# CORTEXA9_WUGEN register map
Vendor: Texas Instruments
Peripheral module from a debugger description file (folder omap4460).
Registers are 32-bit, access per field, reset 0xFFFFFFFF unless marked. A register's access mark holds for its fields unless they carry their own. Offsets are as the file gives them; lines under a group give offsets from that group; [hi:lo] are bit positions; {n}, {i} and the like mark numbered series; 'fields as' and 'values as' point back to an identical list; <NAME> marks a mode.

## CORTEXA9_WUGEN
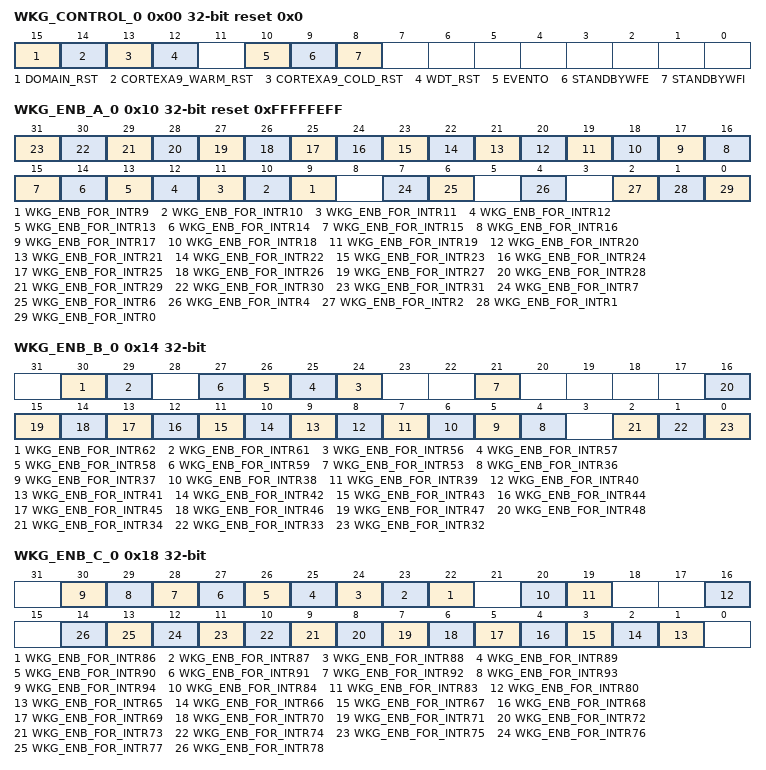
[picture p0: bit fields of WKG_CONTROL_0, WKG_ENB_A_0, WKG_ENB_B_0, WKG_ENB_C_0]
0x00 WKG_CONTROL_0 ro reset 0x0 — Wake-up generator status register for CPU0
  [15] DOMAIN_RST — MPU always-on power domain (PD_ALWON_MPU) reset status bit. It shows if the reset occurred previously. 0x0: no reset occur 0x1: reset occur
  [14] CORTEXA9_WARM_RST — This bit is set when the CORTEXA9_RSTN signal is asserted. 0x0: CORTEXA9_RSTN reset signal has not been asserted 0x1: CORTEXA9_RSTN reset request has been asserted
  [13] CORTEXA9_COLD_RST — This bit is set when the CORTEXA9_PWRON_RSTN signal is asserted. 0x0: CORTEXA9_PWRON_RSTN reset signal has not been asserted 0x1: CORTEXA9_PWRON_RSTN reset request has been asserted
  [12] WDT_RST — This bit is set when the WD timer Reset Request signal from the SCU is asserted. 0x0: WDT reset request has not been asserted 0x1: WDT reset request has been asserted
  [10] EVENTO — EVENTO status bit. The event output signal is active, when one SEV instruction is executed. This bit is set when a rising edge of EVENTO from CPU is detected. 0x0: Rising edge of EVENTO is not detected 0x1: Rising edge of EVENTO is detected
  [9] STANDBYWFE — This bit gives software the visibility to track whether WFE mode have been entered. 0x0: WFE mode has not been entered 0x1: WFE mode has been entered
  [8] STANDBYWFI — This bit gives software the visibility to track whether WFI mode have been entered. 0x0: WFI mode has not been entered 0x1: WFI mode has been entered
0x10 WKG_ENB_A_0 reset 0xFFFFFEFF — This register enables the interrupts (for CPU0) from MA_IRQ_0 to MA_IRQ_31 write 0x0: disable interrupt write 0x1: enable interrupt
  [n] WKG_ENB_FOR_INTR{n} rw (n=9..31), [7] WKG_ENB_FOR_INTR7 rw, [6] WKG_ENB_FOR_INTR6 rw, [4] WKG_ENB_FOR_INTR4 rw, [2] WKG_ENB_FOR_INTR2 rw, [1] WKG_ENB_FOR_INTR1 rw, [0] WKG_ENB_FOR_INTR0 rw
0x14 WKG_ENB_B_0 — This register enables the interrupts (for CPU0) from MA_IRQ_32 to MA_IRQ_63 write 0x0: disable interrupt write 0x1: enable interrupt
  [30] WKG_ENB_FOR_INTR62 rw, [29] WKG_ENB_FOR_INTR61 rw, [n-32] WKG_ENB_FOR_INTR{n} rw (n=56..59), [21] WKG_ENB_FOR_INTR53 rw, [n-32] WKG_ENB_FOR_INTR{n} rw (n=36..48), [2] WKG_ENB_FOR_INTR34 rw, [1] WKG_ENB_FOR_INTR33 rw, [0] WKG_ENB_FOR_INTR32 rw
0x18 WKG_ENB_C_0 — This register enables the interrupts (for CPU0) from MA_IRQ_64 to MA_IRQ_95 write 0x0: disable interrupt write 0x1: enable interrupt
  [n-64] WKG_ENB_FOR_INTR{n} rw (n=86..94), [20] WKG_ENB_FOR_INTR84 rw, [19] WKG_ENB_FOR_INTR83 rw, [16] WKG_ENB_FOR_INTR80 rw, [n-64] WKG_ENB_FOR_INTR{n} rw (n=65..78)
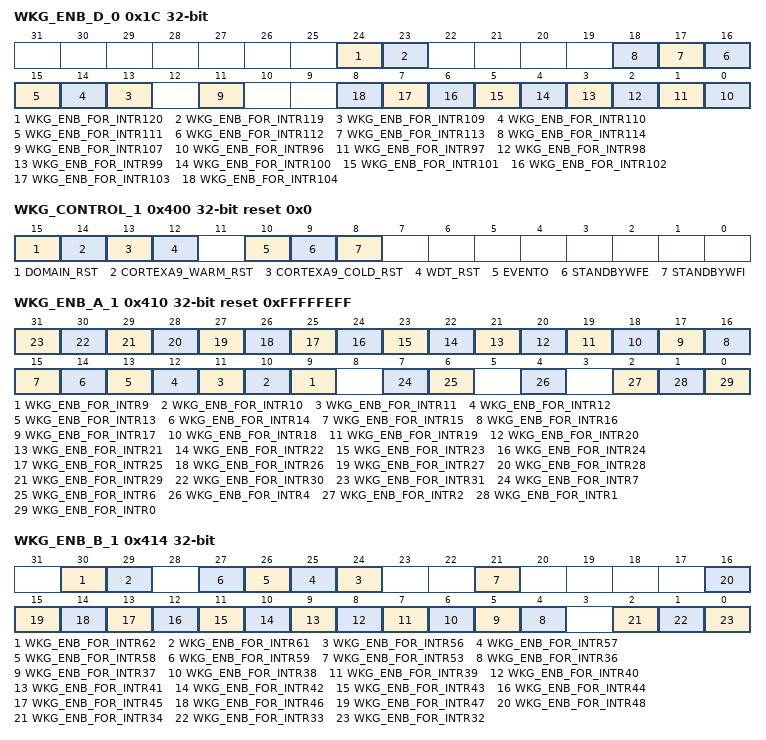
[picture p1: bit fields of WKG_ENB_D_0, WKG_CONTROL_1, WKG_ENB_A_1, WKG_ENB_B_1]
0x1C WKG_ENB_D_0 — This register enables the interrupts (for CPU0) from MA_IRQ_96 to MA_IRQ_127 write 0x0: disable interrupt write 0x1: enable interrupt
  [24] WKG_ENB_FOR_INTR120 rw, [23] WKG_ENB_FOR_INTR119 rw, [n-96] WKG_ENB_FOR_INTR{n} rw (n=109..114), [11] WKG_ENB_FOR_INTR107 rw, [n-96] WKG_ENB_FOR_INTR{n} rw (n=96..104)
0x400 WKG_CONTROL_1 ro reset 0x0 — Wake-up generator status register for CPU1
  fields as WKG_CONTROL_0
0x410 WKG_ENB_A_1 reset 0xFFFFFEFF — This register enables the interrupts (for CPU1) from MA_IRQ_0 to MA_IRQ_31 write 0x0: disable interrupt write 0x1: enable interrupt
  fields as WKG_ENB_A_0
0x414 WKG_ENB_B_1 — This register enables the interrupts (for CPU1) from MA_IRQ_32 to MA_IRQ_63 write 0x0: disable interrupt write 0x1: enable interrupt
  fields as WKG_ENB_B_0
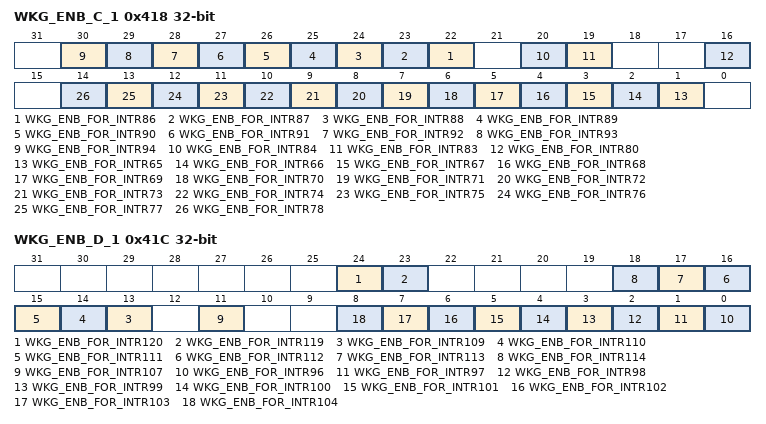
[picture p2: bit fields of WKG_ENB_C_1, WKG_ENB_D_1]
0x418 WKG_ENB_C_1 — This register enables the interrupts (for CPU1) from MA_IRQ_64 to MA_IRQ_95 write 0x0: disable interrupt write 0x1: enable interrupt
  fields as WKG_ENB_C_0
0x41C WKG_ENB_D_1 — This register enables the interrupts (for CPU1) from MA_IRQ_96 to MA_IRQ_127 write 0x0: disable interrupt write 0x1: enable interrupt
  fields as WKG_ENB_D_0
0x800 AUX_CORE_BOOT_0 rw reset 0x0 — This register is used by the ROM code and OS during SMP boot, it is intended to store execution start address of CPU1. When needed, the SMP OS (executing on the CPU0) wakes up CPU1 by executing a SEV command. CPU0 needs to communicate some start-up information (e.g. starting address) to CPU1.
  [31:0] AUX_CORE_BOOT_0 — SMP boot register
0x804 AUX_CORE_BOOT_1 rw reset 0x0 — This register is used by the ROM code and OS during SMP boot, used to indicate boot status to either CPUs. When CPU1 received an event (caused by the SEV command), it continues execution in the ROM which set up the code to branch to the address signaled by CPU0.
  [31:0] AUX_CORE_BOOT_1 — SMP boot register
